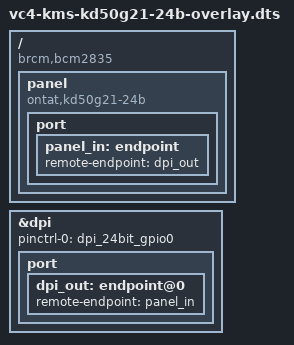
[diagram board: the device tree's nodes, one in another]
/*
 * vc4-kms-v3d-overlay.dts
 */

/dts-v1/;
/plugin/;

#include <dt-bindings/pinctrl/bcm2835.h>

/ {
	compatible = "brcm,bcm2835";

	fragment@0 {
		target-path = "/";
		__overlay__ {
			panel: panel {
				compatible = "ontat,kd50g21-24b", "simple-panel";

				port {
					panel_in: endpoint {
						remote-endpoint = <&dpi_out>;
					};
				};
			};
		};
	};

	fragment@1 {
		target = <&dpi>;
		__overlay__  {
			status = "okay";

			pinctrl-names = "default";
			pinctrl-0 = <&dpi_24bit_gpio0>;

			port {
				dpi_out: endpoint@0 {
					remote-endpoint = <&panel_in>;
				};
			};
		};
	};
};
